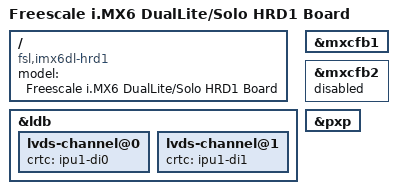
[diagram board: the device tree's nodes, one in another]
/*
 * Copyright (C) 2013 Freescale Semiconductor, Inc.
 *
 * This program is free software; you can redistribute it and/or modify
 * it under the terms of the GNU General Public License version 2 as
 * published by the Free Software Foundation.
 */

/dts-v1/;

#define HRD1_PVT_BOARD
#define TINTO_MP_BOARD

#include "imx6dl.dtsi"
#include "imx6qdl-hrd1.dtsi"

/ {
	model = "Freescale i.MX6 DualLite/Solo HRD1 Board";
	compatible = "fsl,imx6dl-hrd1", "fsl,imx6dl";
};

&ldb {
	lvds-channel@0 {
		crtc = "ipu1-di0";
	};

	lvds-channel@1 {
		crtc = "ipu1-di1";
	};
};

&mxcfb1 {
	status = "okay";
};

&mxcfb2 {
	status = "disabled";
};

&pxp {
	status = "okay";
};

